VERSION ""

NS_ :

BS_:

BU_:
VAL_TABLE_ VSM_ChrgRequest 1 "Request_acrive" 0 "Not_requested" ;
VAL_TABLE_ VSM_ChrgPlugConnected 1 "Plug_active" 0 "Not_plug" ;
VAL_TABLE_ VSM_ChrgReadyToDrive 1 "Ready_to_drive" 0 "Not_ready" ;

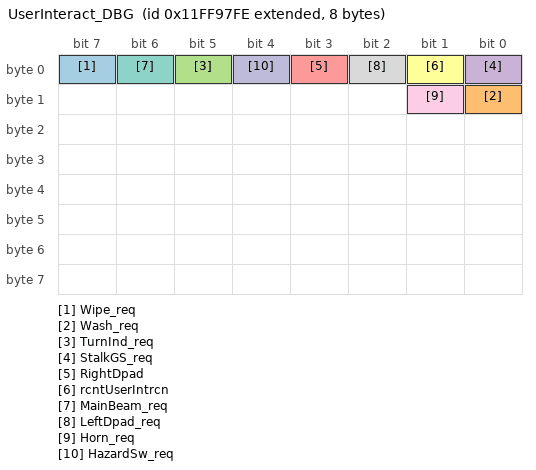
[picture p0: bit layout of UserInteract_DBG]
BO_ 2449446910 UserInteract_DBG: 8 Vector__XXX
 SG_ Wipe_req : 7|1@1+ (1,0) [0|1] "" Vector__XXX
 SG_ Wash_req : 8|1@1+ (1,0) [0|1] "" Vector__XXX
 SG_ TurnInd_req : 5|1@1+ (1,0) [0|1] "" Vector__XXX
 SG_ StalkGS_req : 0|1@1+ (1,0) [0|1] "" Vector__XXX
 SG_ RightDpad : 3|1@1+ (1,0) [0|1] "" Vector__XXX
 SG_ rcntUserIntrcn : 1|1@1+ (1,0) [0|1] "" Vector__XXX
 SG_ MainBeam_req : 6|1@1+ (1,0) [0|1] "" Vector__XXX
 SG_ LeftDpad_req : 2|1@1+ (1,0) [0|1] "" Vector__XXX
 SG_ Horn_req : 9|1@1+ (1,0) [0|1] "" Vector__XXX
 SG_ HazardSw_req : 4|1@1+ (1,0) [0|1] "" Vector__XXX

BO_ 2466225918 HMIUserInteract: 8 Vector__XXX
 SG_ RecentUserInteract : 0|1@1+ (1,0) [0|1] "" Vector__XXX

BO_ 2466225662 SysUserInteract: 8 Vector__XXX
 SG_ StalkGSUserInteract : 0|8@1+ (1,0) [0|255] "" Vector__XXX

CM_ BO_ 2449446910 "For DEBUG-TEST only! Consist of signals that can replace AIN siganls from Analog button block";
CM_ SG_ 2449446910 Wipe_req "Gear selector request from AI";
CM_ SG_ 2449446910 Wash_req "Gear selector request from AI";
CM_ SG_ 2449446910 TurnInd_req "Gear selector request from AI";
CM_ SG_ 2449446910 StalkGS_req "Gear selector request from AI";
CM_ SG_ 2449446910 RightDpad "Gear selector request from AI";
CM_ SG_ 2449446910 rcntUserIntrcn "Gear selector request from AI";
CM_ SG_ 2449446910 MainBeam_req "Gear selector request from AI";
CM_ SG_ 2449446910 LeftDpad_req "Gear selector request from AI";
CM_ SG_ 2449446910 Horn_req "Gear selector request from AI";
CM_ SG_ 2449446910 HazardSw_req "Gear selector request from AI";
CM_ BO_ 2466225918 "For DEBUG-TEST only! Consist of signals that can replace AIN siganls from Analog button block";
CM_ SG_ 2466225918 RecentUserInteract "Gear selector request from AI";
CM_ BO_ 2466225662 "For DEBUG-TEST only! Consist of signals that can replace AIN siganls from Analog button block";
CM_ SG_ 2466225662 StalkGSUserInteract "Gear selector request from AI";
BA_DEF_ BO_  "Producer" STRING ;
BA_DEF_ SG_  "SigType" ENUM  "Default","Range","RangeSigned","ASCII","Discrete","Control","ReferencePGN","DTC","StringDelimiter","StringLength","StringLengthControl","MessageCounter","MessageChecksum";
BA_DEF_ SG_  "GenSigEVName" STRING ;
BA_DEF_ SG_  "GenSigILSupport" ENUM  "No","Yes";
BA_DEF_ SG_  "GenSigSendType" ENUM  "Cyclic","OnWrite","OnWriteWithRepetition","OnChange","OnChangeWithRepetition","IfActive","IfActiveWithRepetition","NoSigSendType";
BA_DEF_ SG_  "GenSigStartValue" INT 0 2147483647;
BA_DEF_ BO_  "GenMsgILSupport" ENUM  "No","Yes";
BA_DEF_ BU_  "NmStationAddress" INT 0 255;
BA_DEF_ BO_  "GenMsgSendType" ENUM  "cyclic","NotUsed","IfActive","NotUsed","NotUsed","NotUsed","NotUsed","NotUsed","noMsgSendType";
BA_DEF_ BO_  "GenMsgRequestable" INT 0 1;
BA_DEF_ BO_  "GenMsgCycleTime" INT 0 3600000;
BA_DEF_  "DBName" STRING ;
BA_DEF_  "BusType" STRING ;
BA_DEF_  "ProtocolType" STRING ;
BA_DEF_ BO_  "VFrameFormat" ENUM  "StandardCAN","ExtendedCAN","reserved","J1939PG";
BA_DEF_DEF_ "Producer" "VSS";
BA_DEF_DEF_  "SigType" "Default";
BA_DEF_DEF_  "GenSigEVName" "Env@Nodename_@Signame";
BA_DEF_DEF_  "GenSigILSupport" "Yes";
BA_DEF_DEF_  "GenSigSendType" "NoSigSendType";
BA_DEF_DEF_  "GenSigStartValue" 0;
BA_DEF_DEF_  "GenMsgILSupport" "Yes";
BA_DEF_DEF_  "NmStationAddress" 254;
BA_DEF_DEF_  "GenMsgSendType" "noMsgSendType";
BA_DEF_DEF_  "GenMsgRequestable" 1;
BA_DEF_DEF_  "GenMsgCycleTime" 0;
BA_DEF_DEF_  "DBName" "";
BA_DEF_DEF_  "BusType" "CAN";
BA_DEF_DEF_  "ProtocolType" "J1939";
BA_DEF_DEF_  "VFrameFormat" "J1939PG";
BA_ "DBName" "VSM";
BA_ "GenMsgCycleTime" BO_ 2449446910 100;
BA_ "GenMsgSendType" BO_ 2449446910 0;
BA_ "GenMsgSendType" BO_ 2466225918 0;
BA_ "GenMsgCycleTime" BO_ 2466225918 100;
BA_ "GenMsgCycleTime" BO_ 2466225662 100;
BA_ "GenMsgSendType" BO_ 2466225662 0;
